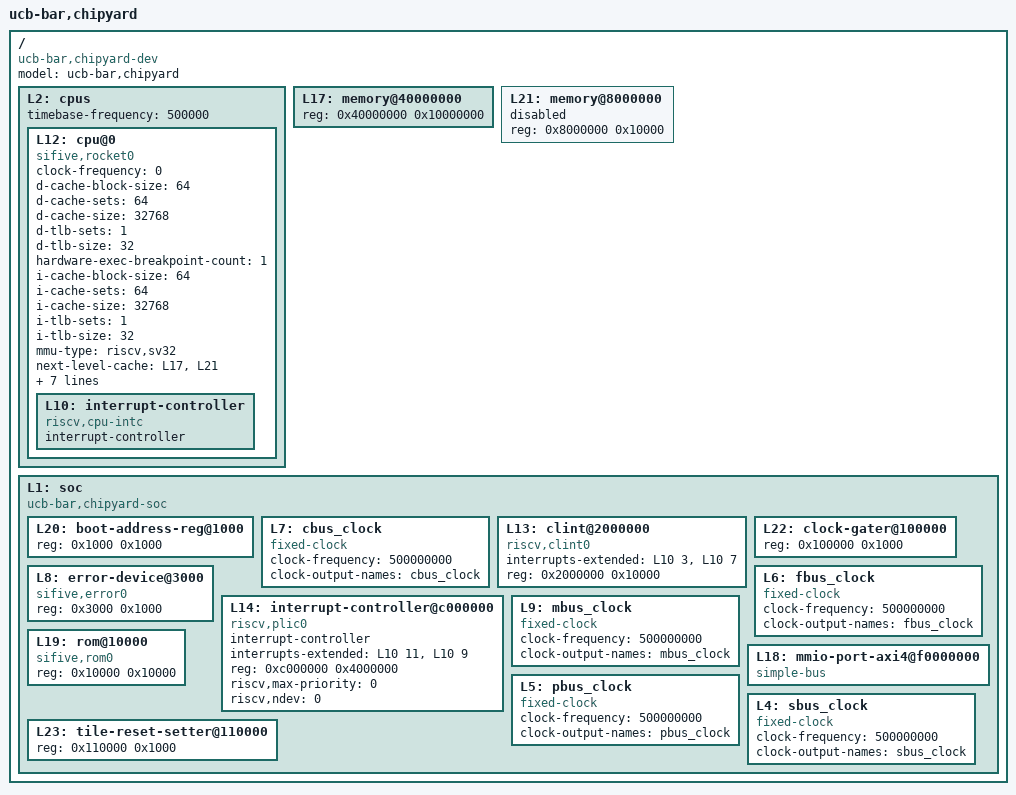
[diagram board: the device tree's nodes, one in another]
/dts-v1/;

/ {
	#address-cells = <1>;
	#size-cells = <1>;
	compatible = "ucb-bar,chipyard-dev";
	model = "ucb-bar,chipyard";
	L2: cpus {
		#address-cells = <1>;
		#size-cells = <0>;
		timebase-frequency = <500000>;
		L12: cpu@0 {
			clock-frequency = <0>;
			compatible = "sifive,rocket0", "riscv";
			d-cache-block-size = <64>;
			d-cache-sets = <64>;
			d-cache-size = <32768>;
			d-tlb-sets = <1>;
			d-tlb-size = <32>;
			device_type = "cpu";
			hardware-exec-breakpoint-count = <1>;
			i-cache-block-size = <64>;
			i-cache-sets = <64>;
			i-cache-size = <32768>;
			i-tlb-sets = <1>;
			i-tlb-size = <32>;
			mmu-type = "riscv,sv32";
			next-level-cache = <&L17 &L21>;
			reg = <0x0>;
			riscv,isa = "rv32imafcbzicsr_zifencei_zihpm_zfh_zba_zbb_zbs_xrocket";
			riscv,pmpgranularity = <4>;
			riscv,pmpregions = <8>;
			status = "okay";
			timebase-frequency = <500000>;
			tlb-split;
			L10: interrupt-controller {
				#interrupt-cells = <1>;
				compatible = "riscv,cpu-intc";
				interrupt-controller;
			};
		};
	};
	L17: memory@40000000 {
		device_type = "memory";
		reg = <0x40000000 0x10000000>;
	};
	L21: memory@8000000 {
		device_type = "memory";
		reg = <0x8000000 0x10000>;
		status = "disabled";
	};
	L1: soc {
		#address-cells = <1>;
		#size-cells = <1>;
		compatible = "ucb-bar,chipyard-soc", "simple-bus";
		ranges;
		L20: boot-address-reg@1000 {
			reg = <0x1000 0x1000>;
			reg-names = "control";
		};
		L7: cbus_clock {
			#clock-cells = <0>;
			clock-frequency = <500000000>;
			clock-output-names = "cbus_clock";
			compatible = "fixed-clock";
		};
		L13: clint@2000000 {
			compatible = "riscv,clint0";
			interrupts-extended = <&L10 3 &L10 7>;
			reg = <0x2000000 0x10000>;
			reg-names = "control";
		};
		L22: clock-gater@100000 {
			reg = <0x100000 0x1000>;
			reg-names = "control";
		};
		L8: error-device@3000 {
			compatible = "sifive,error0";
			reg = <0x3000 0x1000>;
		};
		L6: fbus_clock {
			#clock-cells = <0>;
			clock-frequency = <500000000>;
			clock-output-names = "fbus_clock";
			compatible = "fixed-clock";
		};
		L14: interrupt-controller@c000000 {
			#interrupt-cells = <1>;
			compatible = "riscv,plic0";
			interrupt-controller;
			interrupts-extended = <&L10 11 &L10 9>;
			reg = <0xc000000 0x4000000>;
			reg-names = "control";
			riscv,max-priority = <0>;
			riscv,ndev = <0>;
		};
		L9: mbus_clock {
			#clock-cells = <0>;
			clock-frequency = <500000000>;
			clock-output-names = "mbus_clock";
			compatible = "fixed-clock";
		};
		L18: mmio-port-axi4@f0000000 {
			#address-cells = <1>;
			#size-cells = <1>;
			compatible = "simple-bus";
			ranges = <0xf0000000 0xf0000000 0x10000000>;
		};
		L5: pbus_clock {
			#clock-cells = <0>;
			clock-frequency = <500000000>;
			clock-output-names = "pbus_clock";
			compatible = "fixed-clock";
		};
		L19: rom@10000 {
			compatible = "sifive,rom0";
			reg = <0x10000 0x10000>;
			reg-names = "mem";
		};
		L4: sbus_clock {
			#clock-cells = <0>;
			clock-frequency = <500000000>;
			clock-output-names = "sbus_clock";
			compatible = "fixed-clock";
		};
		L23: tile-reset-setter@110000 {
			reg = <0x110000 0x1000>;
			reg-names = "control";
		};
	};
};
